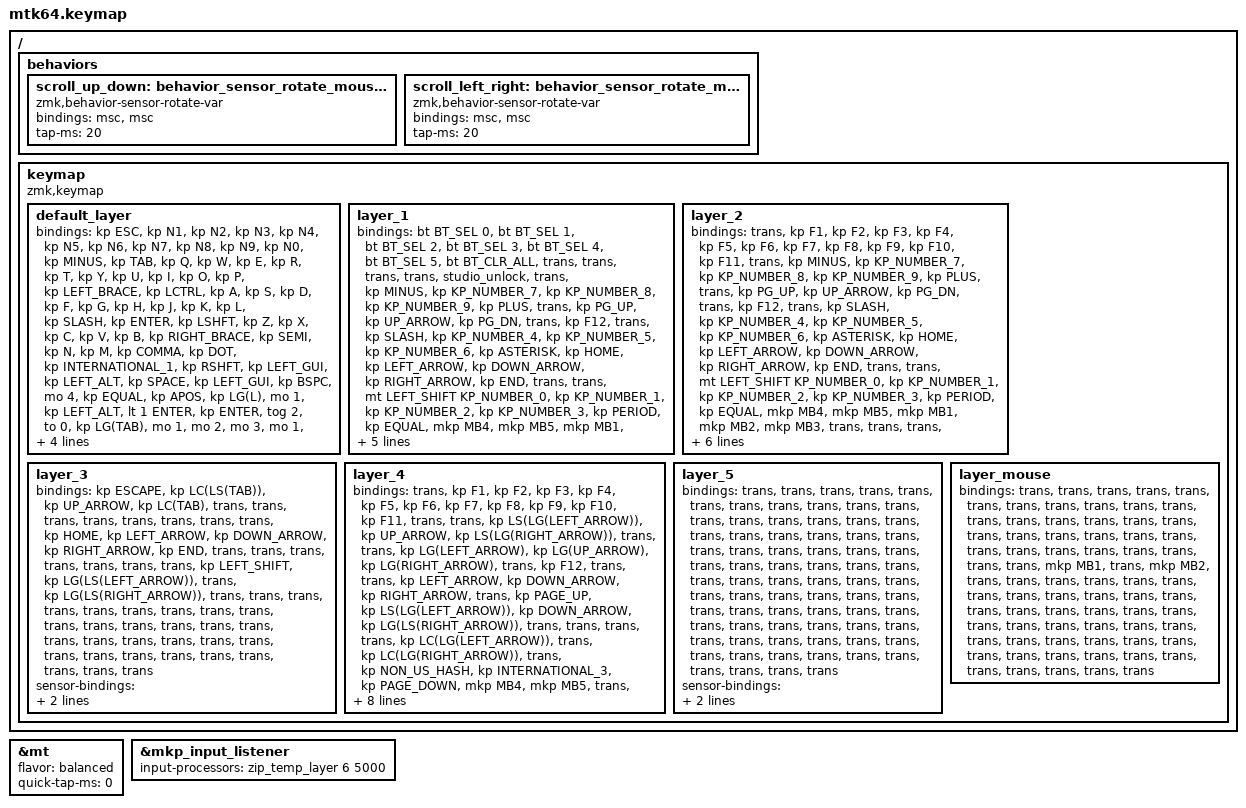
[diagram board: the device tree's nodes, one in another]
#include <input/processors.dtsi>
#include <behaviors.dtsi>
#include <dt-bindings/zmk/bt.h>
#include <dt-bindings/zmk/keys.h>
#include <dt-bindings/zmk/pointing.h>
#include "keycode_japanese.h"

// スクロール量の設定

#define ZMK_POINTING_DEFAULT_SCRL_VAL 100

&mt {
    flavor = "balanced";
    quick-tap-ms = <0>;
};

&mkp_input_listener { input-processors = <&zip_temp_layer 6 5000>; };

/ {
    behaviors {
        // 垂直スクロール用のbehaviorの設定

        scroll_up_down: behavior_sensor_rotate_mouse_wheel_up_down {
            compatible = "zmk,behavior-sensor-rotate-var";
            #sensor-binding-cells = <2>;
            bindings = <&msc>, <&msc>;

            tap-ms = <20>; // スクロールのタップ時間
        };

        // 水平スクロール用のbehaviorの設定

        scroll_left_right: behavior_sensor_rotate_mouse_wheel_left_right {
            compatible = "zmk,behavior-sensor-rotate-var";
            #sensor-binding-cells = <2>;
            bindings = <&msc>, <&msc>;

            tap-ms = <20>; // スクロールのタップ時間
        };
    };
};

/ {
    keymap {
        compatible = "zmk,keymap";

        default_layer {
            bindings = <
&kp ESC  &kp N1  &kp N2  &kp N3  &kp N4  &kp N5  &kp N6  &kp N7  &kp N8  &kp N9  &kp N0  &kp MINUS  &kp TAB  &kp Q  &kp W  &kp E  &kp R  &kp T  &kp Y  &kp U  &kp I  &kp O  &kp P  &kp LEFT_BRACE  &kp LCTRL  &kp A  &kp S  &kp D  &kp F  &kp G  &kp H  &kp J  &kp K  &kp L  &kp SLASH  &kp ENTER  &kp LSHFT  &kp Z  &kp X  &kp C  &kp V  &kp B  &kp RIGHT_BRACE  &kp SEMI  &kp N  &kp M  &kp COMMA  &kp DOT  &kp INTERNATIONAL_1  &kp RSHFT  &kp LEFT_GUI  &kp LEFT_ALT  &kp SPACE  &kp LEFT_GUI  &kp BSPC  &mo 4  &kp EQUAL  &kp APOS  &kp LG(L)  &mo 1  &kp LEFT_ALT  &lt 1 ENTER  &kp ENTER  &tog 2  &to 0  &kp LG(TAB)  &mo 1  &mo 2  &mo 3  &mo 1  &mo 2  &mo 3  &mo 1  &mo 2  &mo 3
            >;

            sensor-bindings = <
                &inc_dec_kp LEFT_ARROW RIGHT_ARROW
                &inc_dec_kp UP_ARROW   DOWN_ARROW
            >;
        };

        layer_1 {
            bindings = <
&bt BT_SEL 0  &bt BT_SEL 1  &bt BT_SEL 2  &bt BT_SEL 3  &bt BT_SEL 4  &bt BT_SEL 5  &bt BT_CLR_ALL  &trans  &trans  &trans  &trans  &studio_unlock  &trans  &kp MINUS  &kp KP_NUMBER_7  &kp KP_NUMBER_8  &kp KP_NUMBER_9  &kp PLUS  &trans  &kp PG_UP  &kp UP_ARROW  &kp PG_DN  &trans  &kp F12  &trans  &kp SLASH  &kp KP_NUMBER_4  &kp KP_NUMBER_5  &kp KP_NUMBER_6  &kp ASTERISK  &kp HOME  &kp LEFT_ARROW  &kp DOWN_ARROW  &kp RIGHT_ARROW  &kp END  &trans  &trans  &mt LEFT_SHIFT KP_NUMBER_0  &kp KP_NUMBER_1  &kp KP_NUMBER_2  &kp KP_NUMBER_3  &kp PERIOD  &kp EQUAL  &mkp MB4  &mkp MB5  &mkp MB1  &mkp MB2  &mkp MB3  &trans  &trans  &trans  &trans  &trans  &trans  &trans  &trans  &trans  &trans  &trans  &trans  &trans  &trans  &trans  &trans  &trans  &trans  &trans  &trans  &trans  &trans  &trans  &trans  &trans  &trans  &trans
            >;
        };

        layer_2 {
            bindings = <
&trans  &kp F1  &kp F2  &kp F3  &kp F4  &kp F5  &kp F6  &kp F7  &kp F8  &kp F9  &kp F10  &kp F11  &trans  &kp MINUS  &kp KP_NUMBER_7  &kp KP_NUMBER_8  &kp KP_NUMBER_9  &kp PLUS  &trans  &kp PG_UP  &kp UP_ARROW  &kp PG_DN  &trans  &kp F12  &trans  &kp SLASH  &kp KP_NUMBER_4  &kp KP_NUMBER_5  &kp KP_NUMBER_6  &kp ASTERISK  &kp HOME  &kp LEFT_ARROW  &kp DOWN_ARROW  &kp RIGHT_ARROW  &kp END  &trans  &trans  &mt LEFT_SHIFT KP_NUMBER_0  &kp KP_NUMBER_1  &kp KP_NUMBER_2  &kp KP_NUMBER_3  &kp PERIOD  &kp EQUAL  &mkp MB4  &mkp MB5  &mkp MB1  &mkp MB2  &mkp MB3  &trans  &trans  &trans  &trans  &trans  &trans  &trans  &trans  &trans  &trans  &trans  &trans  &trans  &trans  &trans  &trans  &trans  &trans  &trans  &trans  &trans  &trans  &trans  &trans  &trans  &trans  &trans
            >;

            sensor-bindings = <
                &inc_dec_kp TAB LS(TAB) 
                &inc_dec_kp PG_UP PG_DN
            >;
        };

        layer_3 {
            bindings = <
&kp ESCAPE  &kp LC(LS(TAB))  &kp UP_ARROW  &kp LC(TAB)  &trans  &trans  &trans  &trans  &trans  &trans  &trans  &trans  &kp HOME  &kp LEFT_ARROW  &kp DOWN_ARROW  &kp RIGHT_ARROW  &kp END  &trans  &trans  &trans  &trans  &trans  &trans  &trans  &kp LEFT_SHIFT  &kp LG(LS(LEFT_ARROW))  &trans  &kp LG(LS(RIGHT_ARROW))  &trans  &trans  &trans  &trans  &trans  &trans  &trans  &trans  &trans  &trans  &trans  &trans  &trans  &trans  &trans  &trans  &trans  &trans  &trans  &trans  &trans  &trans  &trans  &trans  &trans  &trans  &trans  &trans  &trans  &trans
            >;

            sensor-bindings = <
                &scroll_left_right SCRL_LEFT SCRL_RIGHT
                &scroll_up_down SCRL_UP SCRL_DOWN
            >;
        };

        layer_4 {
            bindings = <
&trans  &kp F1  &kp F2  &kp F3  &kp F4  &kp F5  &kp F6  &kp F7  &kp F8  &kp F9  &kp F10  &kp F11  &trans  &trans  &kp LS(LG(LEFT_ARROW))  &kp UP_ARROW  &kp LS(LG(RIGHT_ARROW))  &trans  &trans  &kp LG(LEFT_ARROW)  &kp LG(UP_ARROW)  &kp LG(RIGHT_ARROW)  &trans  &kp F12  &trans  &trans  &kp LEFT_ARROW  &kp DOWN_ARROW  &kp RIGHT_ARROW  &trans  &kp PAGE_UP  &kp LS(LG(LEFT_ARROW))  &kp DOWN_ARROW  &kp LG(LS(RIGHT_ARROW))  &trans  &trans  &trans  &trans  &kp LC(LG(LEFT_ARROW))  &trans  &kp LC(LG(RIGHT_ARROW))  &trans  &kp NON_US_HASH  &kp INTERNATIONAL_3  &kp PAGE_DOWN  &mkp MB4  &mkp MB5  &trans  &trans  &trans  &trans  &trans  &kp GRAVE  &trans  &kp DEL  &trans  &trans  &trans  &trans  &trans  &trans  &trans  &trans  &trans  &trans  &trans  &trans  &trans  &trans  &trans  &trans  &trans  &trans  &trans  &trans
            >;

            sensor-bindings =
                <&scroll_left_right SCRL_LEFT SCRL_RIGHT>,
                <&scroll_up_down SCRL_UP SCRL_DOWN>;
        };

        layer_5 {
            bindings = <
&trans  &trans  &trans  &trans  &trans  &trans  &trans  &trans  &trans  &trans  &trans  &trans  &trans  &trans  &trans  &trans  &trans  &trans  &trans  &trans  &trans  &trans  &trans  &trans  &trans  &trans  &trans  &trans  &trans  &trans  &trans  &trans  &trans  &trans  &trans  &trans  &trans  &trans  &trans  &trans  &trans  &trans  &trans  &trans  &trans  &trans  &trans  &trans  &trans  &trans  &trans  &trans  &trans  &trans  &trans  &trans  &trans  &trans  &trans  &trans  &trans  &trans  &trans  &trans  &trans  &trans  &trans  &trans  &trans  &trans  &trans  &trans  &trans  &trans  &trans
            >;

            sensor-bindings =
                <&inc_dec_kp LS(LEFT_ARROW) LS(RIGHT_ARROW)>,
                <&inc_dec_kp LC(K_SCROLL_UP) LC(K_SCROLL_DOWN)>;
        };

        layer_mouse {
            bindings = <
&trans  &trans  &trans  &trans  &trans  &trans  &trans  &trans  &trans  &trans  &trans  &trans  &trans  &trans  &trans  &trans  &trans  &trans  &trans  &trans  &trans  &trans  &trans  &trans  &trans  &trans  &trans  &trans  &trans  &trans  &trans  &mkp MB1  &trans  &mkp MB2  &trans  &trans  &trans  &trans  &trans  &trans  &trans  &trans  &trans  &trans  &trans  &trans  &trans  &trans  &trans  &trans  &trans  &trans  &trans  &trans  &trans  &trans  &trans  &trans  &trans  &trans  &trans  &trans  &trans  &trans  &trans  &trans  &trans  &trans  &trans  &trans  &trans  &trans  &trans  &trans  &trans
            >;
        };
    };
};
